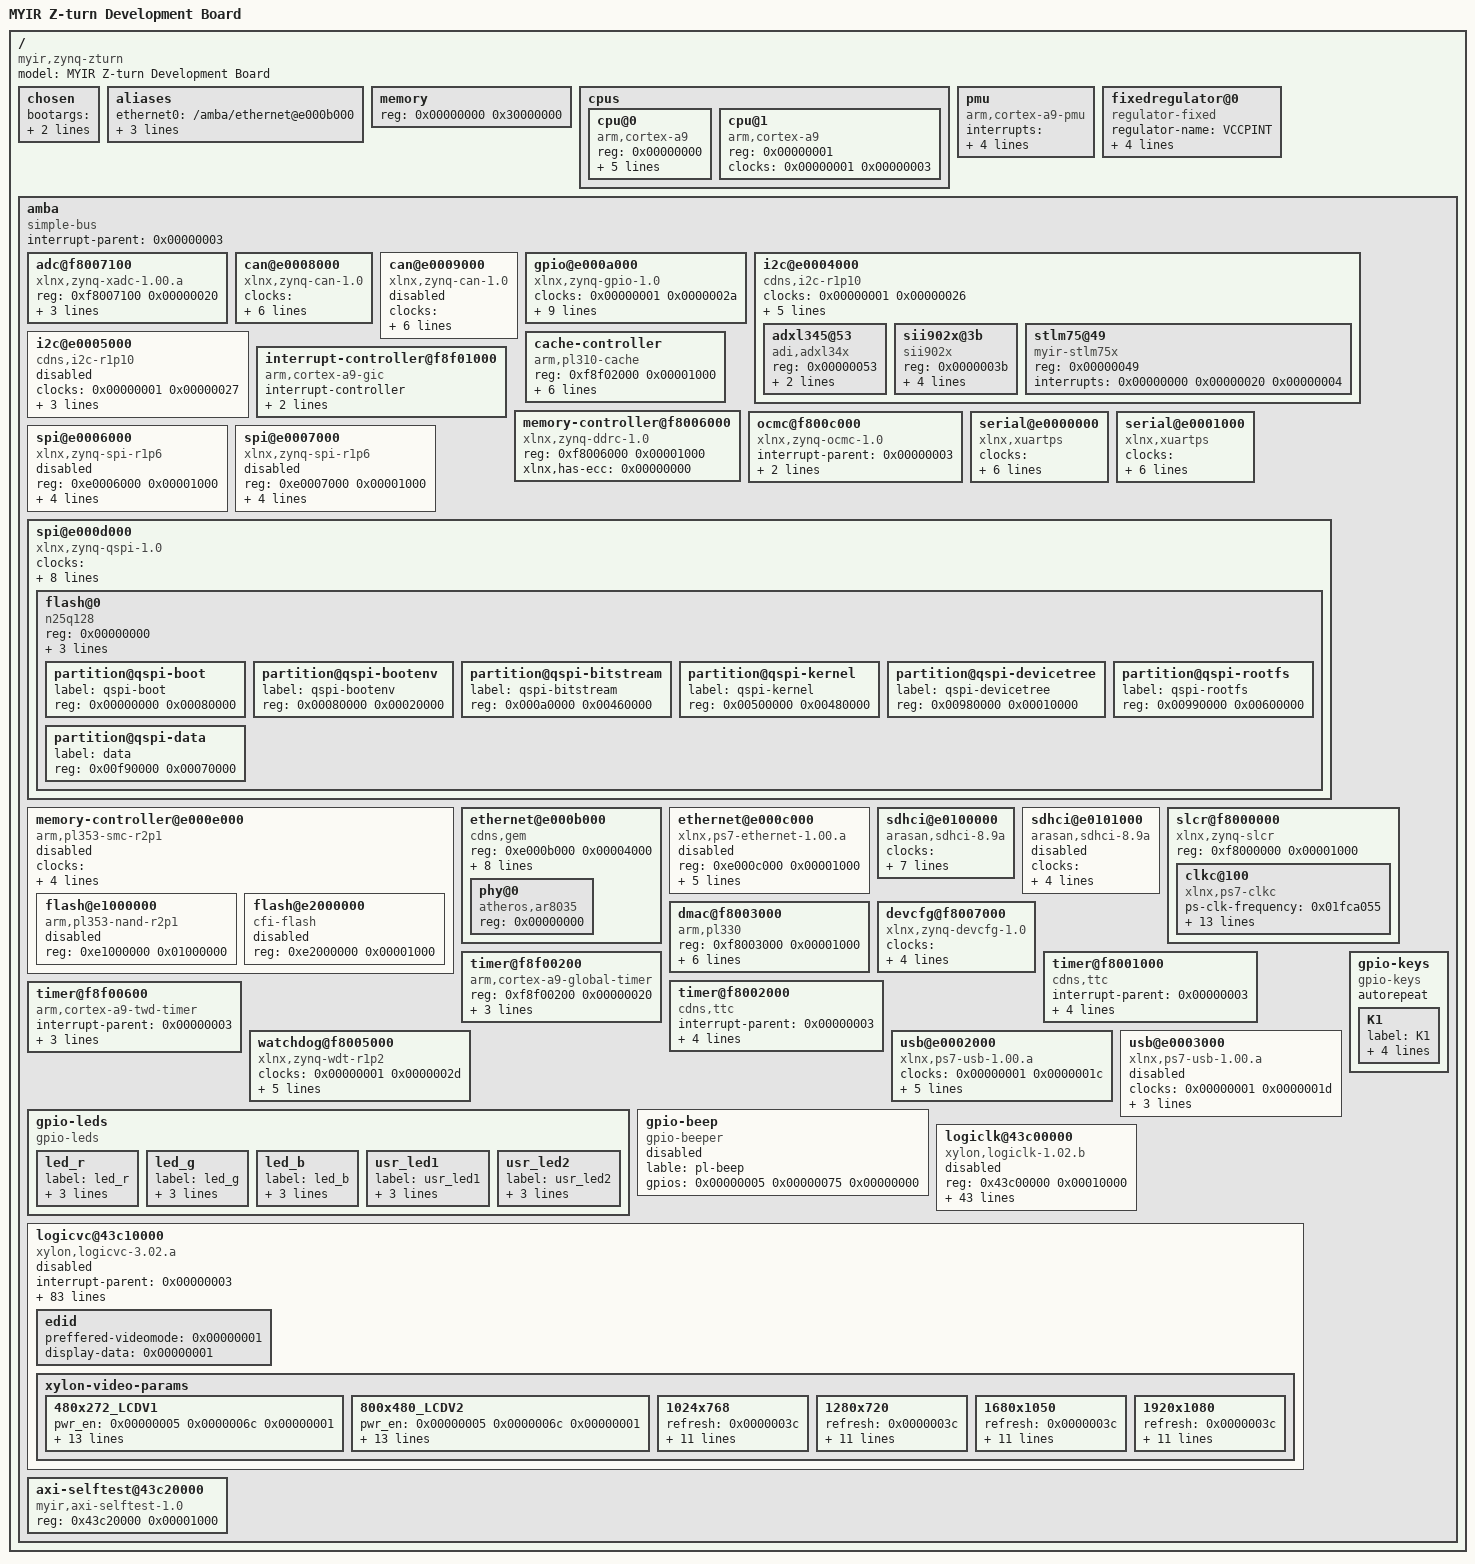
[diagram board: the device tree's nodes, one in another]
/dts-v1/;
// version:		17
// last_comp_version:	16
// boot_cpuid_phys:	0x0

/ {
    #address-cells = <0x00000001>;
    #size-cells = <0x00000001>;
    compatible = "myir,zynq-zturn", "xlnx,zynq-7000";
    model = "MYIR Z-turn Development Board";
    chosen {
        bootargs = "console=ttyPS0,115200 root=/dev/ram rw earlyprintk";
        linux,stdout-path = "/amba/serial@e0001000";
    };
    aliases {
        ethernet0 = "/amba/ethernet@e000b000";
        serial0 = "/amba/serial@e0001000";
        serial1 = "/amba/serial@e0000000";
        spi0 = "/amba/spi@e000d000";
    };
    memory {
        device_type = "memory";
        reg = <0x00000000 0x30000000>;
    };
    cpus {
        #address-cells = <0x00000001>;
        #size-cells = <0x00000000>;
        cpu@0 {
            compatible = "arm,cortex-a9";
            device_type = "cpu";
            reg = <0x00000000>;
            clocks = <0x00000001 0x00000003>;
            clock-latency = <0x000003e8>;
            cpu0-supply = <0x00000002>;
            operating-points = <0x000a2c2b 0x000f4240 0x00051616 0x000f4240>;
        };
        cpu@1 {
            compatible = "arm,cortex-a9";
            device_type = "cpu";
            reg = <0x00000001>;
            clocks = <0x00000001 0x00000003>;
        };
    };
    pmu {
        compatible = "arm,cortex-a9-pmu";
        interrupts = <0x00000000 0x00000005 0x00000004 0x00000000 0x00000006 0x00000004>;
        interrupt-parent = <0x00000003>;
        reg = <0xf8891000 0x00001000 0xf8893000 0x00001000>;
    };
    fixedregulator@0 {
        compatible = "regulator-fixed";
        regulator-name = "VCCPINT";
        regulator-min-microvolt = <0x000f4240>;
        regulator-max-microvolt = <0x000f4240>;
        regulator-boot-on;
        regulator-always-on;
        linux,phandle = <0x00000002>;
        phandle = <0x00000002>;
    };
    amba {
        compatible = "simple-bus";
        #address-cells = <0x00000001>;
        #size-cells = <0x00000001>;
        interrupt-parent = <0x00000003>;
        ranges;
        adc@f8007100 {
            compatible = "xlnx,zynq-xadc-1.00.a";
            reg = <0xf8007100 0x00000020>;
            interrupts = <0x00000000 0x00000007 0x00000004>;
            interrupt-parent = <0x00000003>;
            clocks = <0x00000001 0x0000000c>;
        };
        can@e0008000 {
            compatible = "xlnx,zynq-can-1.0";
            status = "okay";
            clocks = <0x00000001 0x00000013 0x00000001 0x00000024>;
            clock-names = "can_clk", "pclk";
            reg = <0xe0008000 0x00001000>;
            interrupts = <0x00000000 0x0000001c 0x00000004>;
            interrupt-parent = <0x00000003>;
            tx-fifo-depth = <0x00000040>;
            rx-fifo-depth = <0x00000040>;
        };
        can@e0009000 {
            compatible = "xlnx,zynq-can-1.0";
            status = "disabled";
            clocks = <0x00000001 0x00000014 0x00000001 0x00000025>;
            clock-names = "can_clk", "pclk";
            reg = <0xe0009000 0x00001000>;
            interrupts = <0x00000000 0x00000033 0x00000004>;
            interrupt-parent = <0x00000003>;
            tx-fifo-depth = <0x00000040>;
            rx-fifo-depth = <0x00000040>;
        };
        gpio@e000a000 {
            compatible = "xlnx,zynq-gpio-1.0";
            #gpio-cells = <0x00000002>;
            clocks = <0x00000001 0x0000002a>;
            gpio-controller;
            interrupt-parent = <0x00000003>;
            interrupts = <0x00000000 0x00000014 0x00000004>;
            reg = <0xe000a000 0x00001000>;
            emio-gpio-width = <0x00000040>;
            gpio-mask-high = <0x00000000>;
            gpio-mask-low = <0x00005600>;
            xlnx,emio-gpio-width = <0x00000040>;
            xlnx,mio-gpio-mask = <0x00005600>;
            linux,phandle = <0x00000005>;
            phandle = <0x00000005>;
        };
        i2c@e0004000 {
            compatible = "cdns,i2c-r1p10";
            status = "okay";
            clocks = <0x00000001 0x00000026>;
            interrupt-parent = <0x00000003>;
            interrupts = <0x00000000 0x00000019 0x00000004>;
            reg = <0xe0004000 0x00001000>;
            #address-cells = <0x00000001>;
            #size-cells = <0x00000000>;
            clock-frequency = <0x00061a80>;
            xlnx,has-interrupt = <0x00000001>;
            adxl345@53 {
                compatible = "adi,adxl34x", "adxl34x";
                reg = <0x00000053>;
                interrupt-parent = <0x00000003>;
                interrupts = <0x00000000 0x0000001f 0x00000004>;
            };
            sii902x@3b {
                compatible = "sii902x";
                reg = <0x0000003b>;
                interrupt-parent = <0x00000003>;
                interrupts = <0x00000000 0x0000001d 0x00000004>;
                mode_str = "1920x1080";
                bits-per-pixel = <0x00000010>;
            };
            stlm75@49 {
                status = "okay";
                compatible = "myir-stlm75x";
                reg = <0x00000049>;
                interrupts = <0x00000000 0x00000020 0x00000004>;
            };
        };
        i2c@e0005000 {
            compatible = "cdns,i2c-r1p10";
            status = "disabled";
            clocks = <0x00000001 0x00000027>;
            interrupt-parent = <0x00000003>;
            interrupts = <0x00000000 0x00000030 0x00000004>;
            reg = <0xe0005000 0x00001000>;
            #address-cells = <0x00000001>;
            #size-cells = <0x00000000>;
        };
        interrupt-controller@f8f01000 {
            compatible = "arm,cortex-a9-gic";
            #interrupt-cells = <0x00000003>;
            interrupt-controller;
            reg = <0xf8f01000 0x00001000 0xf8f00100 0x00000100>;
            linux,phandle = <0x00000003>;
            phandle = <0x00000003>;
        };
        cache-controller {
            compatible = "arm,pl310-cache";
            reg = <0xf8f02000 0x00001000>;
            arm,data-latency = <0x00000003 0x00000002 0x00000002>;
            arm,tag-latency = <0x00000002 0x00000002 0x00000002>;
            cache-unified;
            cache-level = <0x00000002>;
        };
        memory-controller@f8006000 {
            compatible = "xlnx,zynq-ddrc-1.0";
            reg = <0xf8006000 0x00001000>;
            xlnx,has-ecc = <0x00000000>;
        };
        ocmc@f800c000 {
            compatible = "xlnx,zynq-ocmc-1.0";
            interrupt-parent = <0x00000003>;
            interrupts = <0x00000000 0x00000003 0x00000004>;
            reg = <0xf800c000 0x00001000>;
        };
        serial@e0000000 {
            compatible = "xlnx,xuartps";
            status = "okay";
            clocks = <0x00000001 0x00000017 0x00000001 0x00000028>;
            clock-names = "uart_clk", "pclk";
            reg = <0xe0000000 0x00001000>;
            interrupts = <0x00000000 0x0000001b 0x00000004>;
            current-speed = <0x0001c200>;
            port-number = <0x00000001>;
            xlnx,has-modem = <0x00000000>;
        };
        serial@e0001000 {
            compatible = "xlnx,xuartps";
            status = "okay";
            clocks = <0x00000001 0x00000018 0x00000001 0x00000029>;
            clock-names = "uart_clk", "pclk";
            reg = <0xe0001000 0x00001000>;
            interrupts = <0x00000000 0x00000032 0x00000004>;
            current-speed = <0x0001c200>;
            port-number = <0x00000000>;
            xlnx,has-modem = <0x00000000>;
        };
        spi@e0006000 {
            compatible = "xlnx,zynq-spi-r1p6";
            reg = <0xe0006000 0x00001000>;
            status = "disabled";
            interrupt-parent = <0x00000003>;
            interrupts = <0x00000000 0x0000001a 0x00000004>;
            clocks = <0x00000001 0x00000019 0x00000001 0x00000022>;
            clock-names = "ref_clk", "pclk";
            #address-cells = <0x00000001>;
            #size-cells = <0x00000000>;
        };
        spi@e0007000 {
            compatible = "xlnx,zynq-spi-r1p6";
            reg = <0xe0007000 0x00001000>;
            status = "disabled";
            interrupt-parent = <0x00000003>;
            interrupts = <0x00000000 0x00000031 0x00000004>;
            clocks = <0x00000001 0x0000001a 0x00000001 0x00000023>;
            clock-names = "ref_clk", "pclk";
            #address-cells = <0x00000001>;
            #size-cells = <0x00000000>;
        };
        spi@e000d000 {
            clock-names = "ref_clk", "pclk";
            clocks = <0x00000001 0x0000000a 0x00000001 0x0000002b>;
            compatible = "xlnx,zynq-qspi-1.0";
            status = "okay";
            interrupt-parent = <0x00000003>;
            interrupts = <0x00000000 0x00000013 0x00000004>;
            reg = <0xe000d000 0x00001000>;
            #address-cells = <0x00000001>;
            #size-cells = <0x00000000>;
            is-dual = <0x00000000>;
            num-cs = <0x00000001>;
            xlnx,fb-clk = <0x00000001>;
            xlnx,qspi-mode = <0x00000000>;
            flash@0 {
                compatible = "n25q128";
                reg = <0x00000000>;
                spi-tx-bus-width = <0x00000001>;
                spi-rx-bus-width = <0x00000004>;
                spi-max-frequency = <0x02faf080>;
                #address-cells = <0x00000001>;
                #size-cells = <0x00000001>;
                partition@qspi-boot {
                    label = "qspi-boot";
                    reg = <0x00000000 0x00080000>;
                };
                partition@qspi-bootenv {
                    label = "qspi-bootenv";
                    reg = <0x00080000 0x00020000>;
                };
                partition@qspi-bitstream {
                    label = "qspi-bitstream";
                    reg = <0x000a0000 0x00460000>;
                };
                partition@qspi-kernel {
                    label = "qspi-kernel";
                    reg = <0x00500000 0x00480000>;
                };
                partition@qspi-devicetree {
                    label = "qspi-devicetree";
                    reg = <0x00980000 0x00010000>;
                };
                partition@qspi-rootfs {
                    label = "qspi-rootfs";
                    reg = <0x00990000 0x00600000>;
                };
                partition@qspi-data {
                    label = "data";
                    reg = <0x00f90000 0x00070000>;
                };
            };
        };
        memory-controller@e000e000 {
            #address-cells = <0x00000001>;
            #size-cells = <0x00000001>;
            status = "disabled";
            clock-names = "memclk", "aclk";
            clocks = <0x00000001 0x0000000b 0x00000001 0x0000002c>;
            compatible = "arm,pl353-smc-r2p1";
            interrupt-parent = <0x00000003>;
            interrupts = <0x00000000 0x00000012 0x00000004>;
            ranges;
            reg = <0xe000e000 0x00001000>;
            flash@e1000000 {
                status = "disabled";
                compatible = "arm,pl353-nand-r2p1";
                reg = <0xe1000000 0x01000000>;
                #address-cells = <0x00000001>;
                #size-cells = <0x00000001>;
            };
            flash@e2000000 {
                status = "disabled";
                compatible = "cfi-flash";
                reg = <0xe2000000 0x00001000>;
                #address-cells = <0x00000001>;
                #size-cells = <0x00000001>;
            };
        };
        ethernet@e000b000 {
            compatible = "cdns,gem";
            reg = <0xe000b000 0x00004000>;
            status = "okay";
            interrupts = <0x00000000 0x00000016 0x00000004>;
            clocks = <0x00000001 0x0000001e 0x00000001 0x0000001e 0x00000001 0x0000000d>;
            clock-names = "pclk", "hclk", "tx_clk";
            local-mac-address = [00 0a 35 00 00 00];
            xlnx,has-mdio = <0x00000001>;
            #address-cells = <0x00000001>;
            #size-cells = <0x00000000>;
            interrupt-parent = <0x00000003>;
            phy-mode = "rgmii-id";
            phy-handle = <0x00000004>;
            phy@0 {
                compatible = "atheros,ar8035";
                device_type = "ethernet-phy";
                reg = <0x00000000>;
                linux,phandle = <0x00000004>;
                phandle = <0x00000004>;
            };
        };
        ethernet@e000c000 {
            compatible = "xlnx,ps7-ethernet-1.00.a";
            reg = <0xe000c000 0x00001000>;
            status = "disabled";
            interrupts = <0x00000000 0x0000002d 0x00000004>;
            clocks = <0x00000001 0x0000000e 0x00000001 0x0000001f>;
            clock-names = "ref_clk", "aper_clk";
            local-mac-address = [00 0a 35 00 00 00];
            xlnx,has-mdio = <0x00000001>;
            #address-cells = <0x00000001>;
            #size-cells = <0x00000000>;
        };
        sdhci@e0100000 {
            compatible = "arasan,sdhci-8.9a";
            status = "okay";
            clock-names = "clk_xin", "clk_ahb";
            clocks = <0x00000001 0x00000015 0x00000001 0x00000020>;
            interrupt-parent = <0x00000003>;
            interrupts = <0x00000000 0x00000018 0x00000004>;
            reg = <0xe0100000 0x00001000>;
            xlnx,has-cd = <0x00000001>;
            xlnx,has-power = <0x00000000>;
            xlnx,has-wp = <0x00000001>;
        };
        sdhci@e0101000 {
            compatible = "arasan,sdhci-8.9a";
            status = "disabled";
            clock-names = "clk_xin", "clk_ahb";
            clocks = <0x00000001 0x00000016 0x00000001 0x00000021>;
            interrupt-parent = <0x00000003>;
            interrupts = <0x00000000 0x0000002f 0x00000004>;
            reg = <0xe0101000 0x00001000>;
        };
        slcr@f8000000 {
            #address-cells = <0x00000001>;
            #size-cells = <0x00000001>;
            compatible = "xlnx,zynq-slcr", "syscon";
            reg = <0xf8000000 0x00001000>;
            ranges;
            clkc@100 {
                #clock-cells = <0x00000001>;
                compatible = "xlnx,ps7-clkc";
                ps-clk-frequency = <0x01fca055>;
                fclk-enable = <0x0000000f>;
                clock-output-names = "armpll", "ddrpll", "iopll", "cpu_6or4x", "cpu_3or2x", "cpu_2x", "cpu_1x", "ddr2x", "ddr3x", "dci", "lqspi", "smc", "pcap", "gem0", "gem1", "fclk0", "fclk1", "fclk2", "fclk3", "can0", "can1", "sdio0", "sdio1", "uart0", "uart1", "spi0", "spi1", "dma", "usb0_aper", "usb1_aper", "gem0_aper", "gem1_aper", "sdio0_aper", "sdio1_aper", "spi0_aper", "spi1_aper", "can0_aper", "can1_aper", "i2c0_aper", "i2c1_aper", "uart0_aper", "uart1_aper", "gpio_aper", "lqspi_aper", "smc_aper", "swdt", "dbg_trc", "dbg_apb";
                reg = <0x00000100 0x00000100>;
                linux,phandle = <0x00000001>;
                phandle = <0x00000001>;
            };
        };
        dmac@f8003000 {
            compatible = "arm,pl330", "arm,primecell";
            reg = <0xf8003000 0x00001000>;
            interrupt-parent = <0x00000003>;
            interrupt-names = "abort", "dma0", "dma1", "dma2", "dma3", "dma4", "dma5", "dma6", "dma7";
            interrupts = <0x00000000 0x0000000d 0x00000004 0x00000000 0x0000000e 0x00000004 0x00000000 0x0000000f 0x00000004 0x00000000 0x00000010 0x00000004 0x00000000 0x00000011 0x00000004 0x00000000 0x00000028 0x00000004 0x00000000 0x00000029 0x00000004 0x00000000 0x0000002a 0x00000004 0x00000000 0x0000002b 0x00000004>;
            #dma-cells = <0x00000001>;
            #dma-channels = <0x00000008>;
            #dma-requests = <0x00000004>;
            clocks = <0x00000001 0x0000001b>;
            clock-names = "apb_pclk";
        };
        devcfg@f8007000 {
            clock-names = "ref_clk", "fclk0", "fclk1", "fclk2", "fclk3";
            clocks = <0x00000001 0x0000000c 0x00000001 0x0000000f 0x00000001 0x00000010 0x00000001 0x00000011 0x00000001 0x00000012>;
            compatible = "xlnx,zynq-devcfg-1.0";
            interrupt-parent = <0x00000003>;
            interrupts = <0x00000000 0x00000008 0x00000004>;
            reg = <0xf8007000 0x00000100>;
        };
        timer@f8f00200 {
            compatible = "arm,cortex-a9-global-timer";
            reg = <0xf8f00200 0x00000020>;
            interrupts = <0x00000001 0x0000000b 0x00000301>;
            interrupt-parent = <0x00000003>;
            clocks = <0x00000001 0x00000004>;
        };
        timer@f8001000 {
            interrupt-parent = <0x00000003>;
            interrupts = <0x00000000 0x0000000a 0x00000004 0x00000000 0x0000000b 0x00000004 0x00000000 0x0000000c 0x00000004>;
            compatible = "cdns,ttc";
            clocks = <0x00000001 0x00000006>;
            reg = <0xf8001000 0x00001000>;
        };
        timer@f8002000 {
            interrupt-parent = <0x00000003>;
            interrupts = <0x00000000 0x00000025 0x00000004 0x00000000 0x00000026 0x00000004 0x00000000 0x00000027 0x00000004>;
            compatible = "cdns,ttc";
            clocks = <0x00000001 0x00000006>;
            reg = <0xf8002000 0x00001000>;
        };
        timer@f8f00600 {
            interrupt-parent = <0x00000003>;
            interrupts = <0x00000001 0x0000000d 0x00000301>;
            compatible = "arm,cortex-a9-twd-timer";
            reg = <0xf8f00600 0x00000020>;
            clocks = <0x00000001 0x00000004>;
        };
        watchdog@f8005000 {
            clocks = <0x00000001 0x0000002d>;
            compatible = "xlnx,zynq-wdt-r1p2";
            device_type = "watchdog";
            interrupt-parent = <0x00000003>;
            interrupts = <0x00000000 0x00000009 0x00000001>;
            reg = <0xf8005000 0x00001000>;
            reset = <0x00000000>;
            timeout-sec = <0x0000000a>;
        };
        usb@e0002000 {
            clocks = <0x00000001 0x0000001c>;
            compatible = "xlnx,ps7-usb-1.00.a", "xlnx,zynq-usb-1.00.a";
            status = "okay";
            interrupt-parent = <0x00000003>;
            interrupts = <0x00000000 0x00000015 0x00000004>;
            reg = <0xe0002000 0x00001000>;
            dr_mode = "host";
            phy_type = "ulpi";
        };
        usb@e0003000 {
            clocks = <0x00000001 0x0000001d>;
            compatible = "xlnx,ps7-usb-1.00.a", "xlnx,zynq-usb-1.00.a";
            status = "disabled";
            interrupt-parent = <0x00000003>;
            interrupts = <0x00000000 0x0000002c 0x00000004>;
            reg = <0xe0003000 0x00001000>;
        };
        gpio-leds {
            compatible = "gpio-leds";
            led_r {
                label = "led_r";
                gpios = <0x00000005 0x00000072 0x00000001>;
                default-state = "on";
                linux,default-trigger = "heartbeat";
            };
            led_g {
                label = "led_g";
                gpios = <0x00000005 0x00000073 0x00000001>;
                default-state = "on";
                linux,default-trigger = "heartbeat";
            };
            led_b {
                label = "led_b";
                gpios = <0x00000005 0x00000074 0x00000001>;
                default-state = "on";
                linux,default-trigger = "heartbeat";
            };
            usr_led1 {
                label = "usr_led1";
                gpios = <0x00000005 0x00000000 0x00000001>;
                default-state = "off";
                linux,default-trigger = "none";
            };
            usr_led2 {
                label = "usr_led2";
                gpios = <0x00000005 0x00000009 0x00000001>;
                default-state = "off";
                linux,default-trigger = "none";
            };
        };
        gpio-beep {
            compatible = "gpio-beeper";
            lable = "pl-beep";
            gpios = <0x00000005 0x00000075 0x00000000>;
            status = "disabled";
        };
        gpio-keys {
            compatible = "gpio-keys";
            #address-cells = <0x00000001>;
            #size-cells = <0x00000000>;
            autorepeat;
            K1 {
                label = "K1";
                gpios = <0x00000005 0x00000032 0x00000001>;
                linux,code = <0x00000066>;
                gpio-key,wakeup;
                autorepeat;
            };
        };
        logiclk@43c00000 {
            compatible = "xylon,logiclk-1.02.b";
            reg = <0x43c00000 0x00010000>;
            osc-clk-freq-hz = <0x05f5e100>;
            xlnx,clk-multiply = <0x00000009>;
            xlnx,clk0-divide = <0x0000000c>;
            xlnx,clk1-divide = <0x00000006>;
            xlnx,clk2-divide = <0x00000001>;
            xlnx,clk3-divide = <0x00000001>;
            xlnx,clk4-divide = <0x00000001>;
            xlnx,clk5-divide = <0x00000001>;
            xlnx,drp-bandwidth = "OPTIMIZED";
            xlnx,drp-clkfbout-mult = <0x00000009>;
            xlnx,drp-clkfbout-phase = <0x00000000>;
            xlnx,drp-clkout0-divide = <0x00000006>;
            xlnx,drp-clkout0-duty = <0x0000c350>;
            xlnx,drp-clkout0-phase = <0x00000000>;
            xlnx,drp-clkout1-divide = <0x00000001>;
            xlnx,drp-clkout1-duty = <0x0000c350>;
            xlnx,drp-clkout1-phase = <0x00000000>;
            xlnx,drp-clkout2-divide = <0x00000001>;
            xlnx,drp-clkout2-duty = <0x0000c350>;
            xlnx,drp-clkout2-phase = <0x00000000>;
            xlnx,drp-clkout3-divide = <0x00000001>;
            xlnx,drp-clkout3-duty = <0x0000c350>;
            xlnx,drp-clkout3-phase = <0x00000000>;
            xlnx,drp-clkout4-divide = <0x00000001>;
            xlnx,drp-clkout4-duty = <0x0000c350>;
            xlnx,drp-clkout4-phase = <0x00000000>;
            xlnx,drp-clkout5-divide = <0x00000001>;
            xlnx,drp-clkout5-duty = <0x0000c350>;
            xlnx,drp-clkout5-phase = <0x00000000>;
            xlnx,drp-divclk-divide = <0x00000001>;
            xlnx,ip-license-type = <0x00000001>;
            xlnx,ip-major-revision = <0x00000001>;
            xlnx,ip-minor-revision = <0x00000002>;
            xlnx,ip-patch-level = <0x00000001>;
            xlnx,regs-interface = <0x00000002>;
            xlnx,rst-polarity = <0x00000000>;
            xlnx,splb-awidth = <0x00000020>;
            xlnx,splb-dwidth = <0x00000020>;
            xlnx,splb-mid-width = <0x00000001>;
            xlnx,splb-native-dwidth = <0x00000020>;
            xlnx,splb-num-masters = <0x00000002>;
            xlnx,use-clk-drp = <0x00000001>;
            xlnx,use-vlink-clk = <0x00000000>;
            status = "disabled";
        };
        logicvc@43c10000 {
            compatible = "xylon,logicvc-3.02.a";
            interrupt-parent = <0x00000003>;
            interrupts = <0x00000000 0x0000001e 0x00000004>;
            reg = <0x43c10000 0x00010000>;
            xlnx,buffer-0-offset = <0x00000438>;
            xlnx,buffer-1-offset = <0x00000438>;
            xlnx,buffer-2-offset = <0x00000438>;
            xlnx,buffer-3-offset = <0x00000438>;
            xlnx,buffer-4-offset = <0x00000438>;
            xlnx,display-color-space = <0x00000000>;
            xlnx,display-interface = <0x00000000>;
            xlnx,dvi-clk-mode = <0x00000000>;
            xlnx,e-data-width = <0x00000018>;
            xlnx,e-layer = <0x00000000>;
            xlnx,increase-fifo = <0x00000004>;
            xlnx,ip-license-check = <0x00000001>;
            xlnx,ip-license-type = <0x00000001>;
            xlnx,ip-major-revision = <0x00000003>;
            xlnx,ip-minor-revision = <0x00000002>;
            xlnx,ip-patch-level = <0x00000000>;
            xlnx,ip-time-before-break = <0x00000001>;
            xlnx,layer-0-alpha-mode = <0x00000001>;
            xlnx,layer-0-data-width = <0x00000018>;
            xlnx,layer-0-offset = <0x00001c7a>;
            xlnx,layer-0-type = <0x00000000>;
            xlnx,layer-1-alpha-mode = <0x00000000>;
            xlnx,layer-1-data-width = <0x00000018>;
            xlnx,layer-1-offset = <0x00000fd2>;
            xlnx,layer-1-type = <0x00000000>;
            xlnx,layer-2-alpha-mode = <0x00000000>;
            xlnx,layer-2-data-width = <0x00000018>;
            xlnx,layer-2-offset = <0x00000000>;
            xlnx,layer-2-type = <0x00000000>;
            xlnx,layer-3-alpha-mode = <0x00000003>;
            xlnx,layer-3-data-width = <0x00000008>;
            xlnx,layer-3-offset = <0x000032a0>;
            xlnx,layer-3-type = <0x00000000>;
            xlnx,layer-4-alpha-mode = <0x00000000>;
            xlnx,layer-4-data-width = <0x00000018>;
            xlnx,layer-4-offset = <0x00002000>;
            xlnx,layer-4-type = <0x00000000>;
            xlnx,lvds-data-width = <0x00000004>;
            xlnx,mem-burst = <0x00000004>;
            xlnx,mem-byte-swap = <0x00000000>;
            xlnx,mem-little-endian = <0x00000001>;
            xlnx,mplb-awidth = <0x00000020>;
            xlnx,mplb-dwidth = <0x00000040>;
            xlnx,mplb-num-masters = <0x00000008>;
            xlnx,mplb-priority = <0x00000003>;
            xlnx,mplb-smallest-slave = <0x00000020>;
            xlnx,num-of-layers = <0x00000003>;
            xlnx,opb-awidth = <0x00000020>;
            xlnx,opb-dwidth = <0x00000020>;
            xlnx,pixel-data-width = <0x00000010>;
            xlnx,little-endian = <0x00000001>;
            xlnx,readable-regs = <0x00000001>;
            xlnx,reg-byte-swap = <0x00000000>;
            xlnx,regs-interface = <0x00000002>;
            xlnx,row-stride = <0x00000800>;
            xlnx,splb-awidth = <0x00000020>;
            xlnx,splb-dwidth = <0x00000020>;
            xlnx,splb-mid-width = <0x00000001>;
            xlnx,splb-native-dwidth = <0x00000020>;
            xlnx,splb-num-masters = <0x00000002>;
            xlnx,use-e-parallel-input = <0x00000000>;
            xlnx,use-e-vclk-bufgmux = <0x00000000>;
            xlnx,use-multiplier = <0x00000002>;
            xlnx,vmem-baseaddr = <0x30000000>;
            xlnx,vmem-highaddr = <0x3fffffff>;
            pixel-clock-source = <0x00000002>;
            pixel-data-invert = <0x00000000>;
            pixel-clock-active-high = <0x00000000>;
            pixel-component-format = "ARGB";
            pixel-component-layer = <0x00000000 0x00000001 0x00000002>;
            xlnx,use-vclk2 = <0x00000001>;
            xlnx,use-xtreme-dsp = <0x00000001>;
            xlnx,vclk-period = <0x000061a8>;
            xlnx,vmem-interface = <0x00000002>;
            xlnx,xcolor = <0x00000000>;
            xlnx,xmb-data-bus-width = <0x00000040>;
            xlnx,use-background = <0x00000001>;
            xlnx,use-size-position = <0x00000001>;
            active-layer = <0x00000001>;
            videomode = "1280x720";
            edid {
                preffered-videomode = <0x00000001>;
                display-data = <0x00000001>;
            };
            xylon-video-params {
                480x272_LCDV1 {
                    pwr_en = <0x00000005 0x0000006c 0x00000001>;
                    bl_en = <0x00000005 0x0000006d 0x00000001>;
                    refresh = <0x0000003c>;
                    xres = <0x000001e0>;
                    yres = <0x00000110>;
                    pixclock-khz = <0x00002710>;
                    left-margin = <0x00000028>;
                    right-margin = <0x00000028>;
                    upper-margin = <0x0000001d>;
                    lower-margin = <0x0000000d>;
                    hsync-len = <0x00000030>;
                    vsync-len = <0x00000003>;
                    sync = <0x00000000>;
                    vmode = <0x00000000>;
                };
                800x480_LCDV2 {
                    pwr_en = <0x00000005 0x0000006c 0x00000001>;
                    bl_en = <0x00000005 0x0000006d 0x00000001>;
                    refresh = <0x0000003c>;
                    xres = <0x00000320>;
                    yres = <0x000001e0>;
                    pixclock-khz = <0x00008232>;
                    left-margin = <0x000000d2>;
                    right-margin = <0x0000002e>;
                    upper-margin = <0x00000016>;
                    lower-margin = <0x00000017>;
                    hsync-len = <0x00000014>;
                    vsync-len = <0x0000000a>;
                    sync = <0x00000000>;
                    vmode = <0x00000000>;
                };
                1024x768 {
                    refresh = <0x0000003c>;
                    xres = <0x00000400>;
                    yres = <0x00000300>;
                    pixclock-khz = <0x0000fde8>;
                    left-margin = <0x000000a0>;
                    right-margin = <0x00000018>;
                    upper-margin = <0x0000001d>;
                    lower-margin = <0x00000003>;
                    hsync-len = <0x00000088>;
                    vsync-len = <0x00000006>;
                    sync = <0x00000001>;
                    vmode = <0x00000000>;
                };
                1280x720 {
                    refresh = <0x0000003c>;
                    xres = <0x00000500>;
                    yres = <0x000002d0>;
                    pixclock-khz = <0x0001220a>;
                    left-margin = <0x000000dc>;
                    right-margin = <0x0000006e>;
                    upper-margin = <0x00000014>;
                    lower-margin = <0x00000005>;
                    hsync-len = <0x00000028>;
                    vsync-len = <0x00000005>;
                    sync = <0x00000001>;
                    vmode = <0x00000000>;
                };
                1680x1050 {
                    refresh = <0x0000003c>;
                    xres = <0x00000690>;
                    yres = <0x0000041a>;
                    pixclock-khz = <0x0001d0d8>;
                    left-margin = <0x00000050>;
                    right-margin = <0x00000030>;
                    upper-margin = <0x00000015>;
                    lower-margin = <0x00000003>;
                    hsync-len = <0x00000020>;
                    vsync-len = <0x00000006>;
                    sync = <0x00000000>;
                    vmode = <0x00000000>;
                };
                1920x1080 {
                    refresh = <0x0000003c>;
                    xres = <0x00000780>;
                    yres = <0x00000438>;
                    pixclock-khz = <0x00024414>;
                    left-margin = <0x00000094>;
                    right-margin = <0x00000058>;
                    upper-margin = <0x00000024>;
                    lower-margin = <0x00000004>;
                    hsync-len = <0x0000002c>;
                    vsync-len = <0x00000005>;
                    sync = <0x00000000>;
                    vmode = <0x00000000>;
                };
            };
            status = "disabled";
        };
        axi-selftest@43c20000 {
            compatible = "myir,axi-selftest-1.0";
            reg = <0x43c20000 0x00001000>;
            status = "okay";
        };
    };
};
